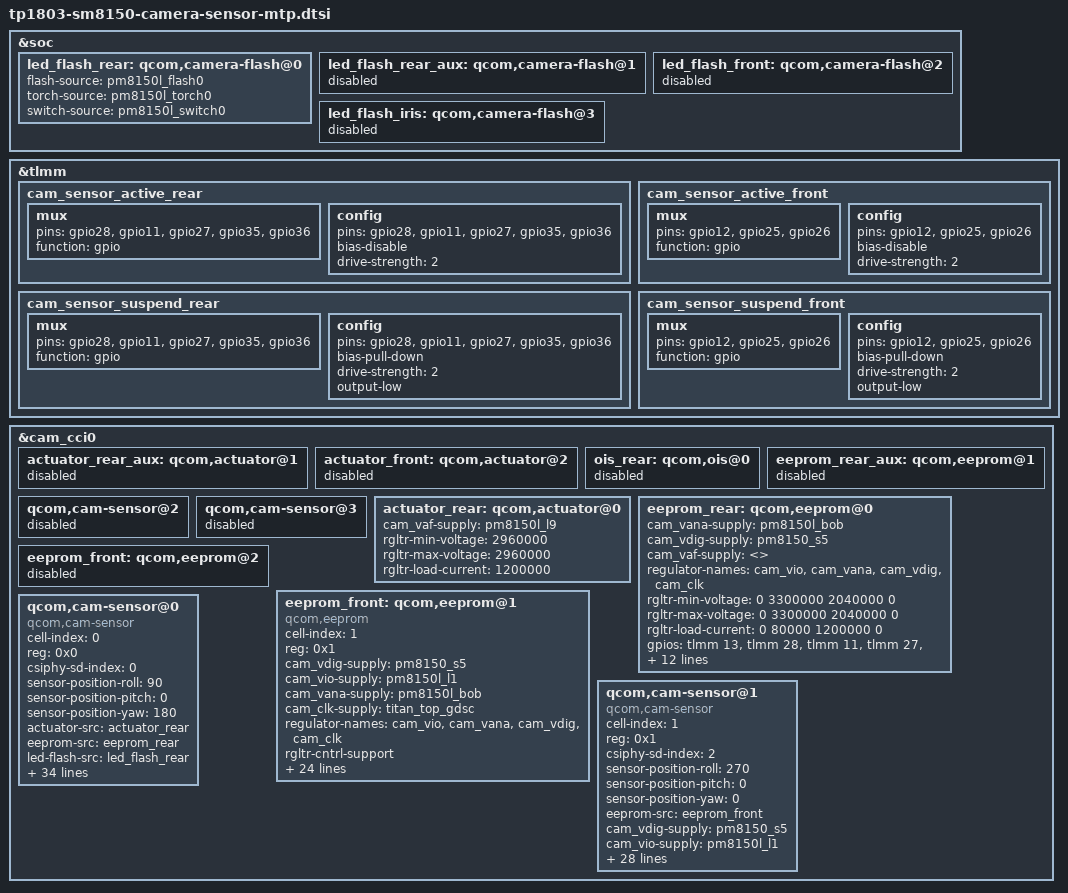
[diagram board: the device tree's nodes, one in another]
// SPDX-License-Identifier: BSD-3-Clause
/*
 * Copyright (c) 2021, Daniel Jacob Chittoor <djchittoor47@gmail.com>
 */

&soc {

	led_flash_rear: qcom,camera-flash@0 {
		flash-source = <&pm8150l_flash0>;
		torch-source = <&pm8150l_torch0>;
		switch-source = <&pm8150l_switch0>;
	};
	
	led_flash_rear_aux: qcom,camera-flash@1 {
		status = "disabled";
	};
	
	led_flash_front: qcom,camera-flash@2 {
		status = "disabled";
	};
	
	led_flash_iris: qcom,camera-flash@3  {
	    status = "disabled";
	};

};

&tlmm {
	/delete-node/ cam_sensor_front_active;
	/delete-node/ cam_sensor_front_suspend;
	/delete-node/ cam_sensor_rear_active;
	/delete-node/ cam_sensor_rear_suspend;

	cam_sensor_active_rear: cam_sensor_active_rear {
		/* RESET REAR */
		mux {
			pins = "gpio28", "gpio11", "gpio27", "gpio35", "gpio36";
			function = "gpio";
		};

		config {
			pins = "gpio28", "gpio11", "gpio27", "gpio35", "gpio36";
			bias-disable; /* No PULL */
			drive-strength = <2>; /* 2 MA */
		};
	};

	cam_sensor_suspend_rear: cam_sensor_suspend_rear {
		/* RESET REAR */
		mux {
			pins = "gpio28", "gpio11", "gpio27", "gpio35", "gpio36";
			function = "gpio";
		};

		config {
			pins = "gpio28", "gpio11", "gpio27", "gpio35", "gpio36";
			bias-pull-down; /* PULL DOWN */
			drive-strength = <2>; /* 2 MA */
			output-low;
		};
	};

	cam_sensor_active_front: cam_sensor_active_front {
		/* RESET FRONT */
		mux {
			pins = "gpio12", "gpio25", "gpio26";
			function = "gpio";
		};

		config {
			pins = "gpio12", "gpio25", "gpio26";
			bias-disable; /* No PULL */
			drive-strength = <2>; /* 2 MA */
		};
	};

	cam_sensor_suspend_front: cam_sensor_suspend_front {
		/* RESET FRONT */
		mux {
			pins = "gpio12", "gpio25", "gpio26";
			function = "gpio";
		};

		config {
			pins = "gpio12", "gpio25", "gpio26";
			bias-pull-down; /* PULL DOWN */
			drive-strength = <2>; /* 2 MA */
			output-low;
		};
	};
};



&cam_cci0 {

	actuator_rear_aux: qcom,actuator@1 {
		status = "disabled";
	};

	actuator_front: qcom,actuator@2 {
		status = "disabled";
	};

	ois_rear: qcom,ois@0 {
		status = "disabled";
	};

	eeprom_rear_aux: qcom,eeprom@1 {
		status = "disabled";
	};

	qcom,cam-sensor@2 {
		status = "disabled";
	};

    qcom,cam-sensor@3 {
        status = "disabled";
    };

	actuator_rear: qcom,actuator@0 {
		cam_vaf-supply = <&pm8150l_l9>;
		rgltr-min-voltage = <2960000>;
		rgltr-max-voltage = <2960000>;
		rgltr-load-current = <1200000>;
	};

	eeprom_rear: qcom,eeprom@0 {
		cam_vana-supply = <&pm8150l_bob>;
		cam_vdig-supply = <&pm8150_s5>;
		cam_vaf-supply = <>;
		regulator-names = "cam_vio", "cam_vana", "cam_vdig", "cam_clk";
		rgltr-min-voltage = <0 3300000 2040000 0>;
		rgltr-max-voltage = <0 3300000 2040000 0>;
		rgltr-load-current = <0 80000 1200000 0>;

		gpios = <&tlmm 13 0>,
			<&tlmm 28 0>,
			<&tlmm 11 0>,
			<&tlmm 27 0>,
			<&tlmm 35 0>,
			<&tlmm 36 0>;

		gpio-vana = <2>;
		gpio-vdig = <3>;
		gpio-custom1 = <4>;
		gpio-custom2 = <5>;
		gpio-req-tbl-num = <0 1 2 3 4 5>;
		gpio-req-tbl-flags = <1 0 0 0 0 0>;
		gpio-req-tbl-label = "CAMIF_MCLK0",
					"CAM_RESET0",
					"CAM_VANA0",
					"CAM_VDIG0",
					"CAM_CUSTOM1",
					"CAM_CUSTOM2";

		cci-device = <0>;
		clock-rates = <19200000>;
	};

	eeprom_front: qcom,eeprom@2 {
		status = "disabled";
	};

	eeprom_front: qcom,eeprom@1 {
		cell-index = <1>;
		reg = <0x1>;
		compatible = "qcom,eeprom";
		cam_vdig-supply = <&pm8150_s5>;
		cam_vio-supply = <&pm8150l_l1>;
		cam_vana-supply = <&pm8150l_bob>;
		cam_clk-supply = <&titan_top_gdsc>;
		regulator-names = "cam_vio", "cam_vana", "cam_vdig", "cam_clk";
		rgltr-cntrl-support;
		pwm-switch;
		rgltr-min-voltage = <0 3300000 2040000 0>;
		rgltr-max-voltage = <0 3300000 2040000 0>;
		rgltr-load-current = <0 80000 1200000 0>;
		gpio-no-mux = <0>;
		pinctrl-names = "cam_default", "cam_suspend";
		pinctrl-0 = <&cam_sensor_mclk2_active
				 &cam_sensor_active_front>;
		pinctrl-1 = <&cam_sensor_mclk2_suspend
				 &cam_sensor_suspend_front>;
		gpios = <&tlmm 15 0>,
			<&tlmm 12 0>,
			<&tlmm 25 0>,
			<&tlmm 26 0>;
		gpio-reset = <1>;
		gpio-vana = <2>;
		gpio-vdig = <3>;
		gpio-req-tbl-num = <0 1 2 3>;
		gpio-req-tbl-flags = <1 0 0 0>;
		gpio-req-tbl-label = "CAMIF_MCLK2",
					"CAM_RESET2",
					"CAM_VANA2",
					"CAM_VDIG2";
		sensor-position = <1>;
		sensor-mode = <0>;
		cci-device = <1>;
		cci-master = <0>;
		status = "ok";
		clocks = <&clock_camcc CAM_CC_MCLK2_CLK>;
		clock-names = "cam_clk";
		clock-cntl-level = "turbo";
		clock-rates = <19200000>;
	};


	qcom,cam-sensor@0 {
		cell-index = <0>;
		compatible = "qcom,cam-sensor";
		reg = <0x0>;
		csiphy-sd-index = <0>;
		sensor-position-roll = <90>;
		sensor-position-pitch = <0>;
		sensor-position-yaw = <180>;
		actuator-src = <&actuator_rear>;
		eeprom-src = <&eeprom_rear>;
		led-flash-src = <&led_flash_rear>;
		cam_vio-supply = <&pm8150l_l1>;
		cam_vana-supply = <&pm8150l_bob>;
		cam_vdig-supply = <&pm8150_s5>;
		cam_clk-supply = <&titan_top_gdsc>;
		regulator-names = "cam_vio", "cam_vana", "cam_vdig",
			"cam_clk";
		rgltr-cntrl-support;
		pwm-switch;
		rgltr-min-voltage = <0 3300000 2040000 0>;
		rgltr-max-voltage = <0 3300000 2040000 0>;
		rgltr-load-current = <0 80000 1200000 0>;
		gpio-no-mux = <0>;
		pinctrl-names = "cam_default", "cam_suspend";
		pinctrl-0 = <&cam_sensor_mclk0_active
				&cam_sensor_active_rear>;
		pinctrl-1 = <&cam_sensor_mclk0_suspend
				&cam_sensor_suspend_rear>;
		gpios = <&tlmm 13 0>,
			<&tlmm 28 0>,
			<&tlmm 11 0>,
			<&tlmm 27 0>,
			<&tlmm 35 0>,
			<&tlmm 36 0>;
		gpio-reset = <1>;
		gpio-vana = <2>;
		gpio-vdig = <3>;
		gpio-custom1 = <4>;
		gpio-custom2 = <5>;
		gpio-req-tbl-num = <0 1 2 3 4 5>;
		gpio-req-tbl-flags = <1 0 0 0 0 0>;
		gpio-req-tbl-label = "CAMIF_MCLK0",
					"CAM_RESET0",
					"CAM_VANA0",
					"CAM_VDIG0",
					"CAM_CUSTOM1",
					"CAM_CUSTOM2";
		sensor-mode = <0>;
		cci-device = <0>;
		cci-master = <0>;
		status = "ok";
		clocks = <&clock_camcc CAM_CC_MCLK0_CLK>;
		clock-names = "cam_clk";
		clock-cntl-level = "turbo";
		clock-rates = <19200000>;
	};

	qcom,cam-sensor@1 {
		cell-index = <1>;
		compatible = "qcom,cam-sensor";
		reg = <0x1>;
		csiphy-sd-index = <2>;
		sensor-position-roll = <270>;
		sensor-position-pitch = <0>;
		sensor-position-yaw = <0>;
		eeprom-src = <&eeprom_front>;
		//cam_bob-supply = <&pm8150l_bob>;
		cam_vdig-supply = <&pm8150_s5>;
		cam_vio-supply = <&pm8150l_l1>;
		cam_vana-supply = <&pm8150l_bob>;
		cam_clk-supply = <&titan_top_gdsc>;
		regulator-names = "cam_vio", "cam_vana", "cam_vdig", "cam_clk";
		rgltr-cntrl-support;
		pwm-switch;
		rgltr-min-voltage = <0 3300000 2040000 0>;
		rgltr-max-voltage = <0 3300000 2040000 0>;
		rgltr-load-current = <0 80000 1200000 0>;
		gpio-no-mux = <0>;
		pinctrl-names = "cam_default", "cam_suspend";
		pinctrl-0 = <&cam_sensor_mclk2_active
				 &cam_sensor_active_front>;
		pinctrl-1 = <&cam_sensor_mclk2_suspend
				 &cam_sensor_suspend_front>;
		gpios = <&tlmm 15 0>,
			<&tlmm 12 0>,
			<&tlmm 25 0>,
			<&tlmm 26 0>;
		gpio-reset = <1>;
		gpio-vana = <2>;
		gpio-vdig = <3>;
		gpio-req-tbl-num = <0 1 2 3>;
		gpio-req-tbl-flags = <1 0 0 0>;
		gpio-req-tbl-label = "CAMIF_MCLK2",
					"CAM_RESET2",
					"CAM_VANA2",
					"CAM_VDIG2";

		sensor-mode = <0>;
		cci-device = <1>;
		cci-master = <0>;
		status = "ok";
		clocks = <&clock_camcc CAM_CC_MCLK2_CLK>;
		clock-names = "cam_clk";
		clock-cntl-level = "turbo";
		clock-rates = <19200000>;
	};
};
